VERSION ""

NS_ :

BS_:

BU_: BRAKE STEERING THROTTLE FAULT

BO_ 80 BRAKE_ENABLE: 8 BRAKE
 SG_ BRAKE_ENABLE_magic : 0|16@1+ (1,0) [0|0] "" BRAKE
 SG_ BRAKE_ENABLE_reserved : 16|48@1+ (1,0) [0|0] "" BRAKE

BO_ 81 BRAKE_DISABLE: 8 BRAKE
 SG_ BRAKE_DISABLE_magic : 0|16@1+ (1,0) [0|0] "" BRAKE
 SG_ BRAKE_DISABLE_reserved : 16|48@1+ (1,0) [0|0] "" BRAKE

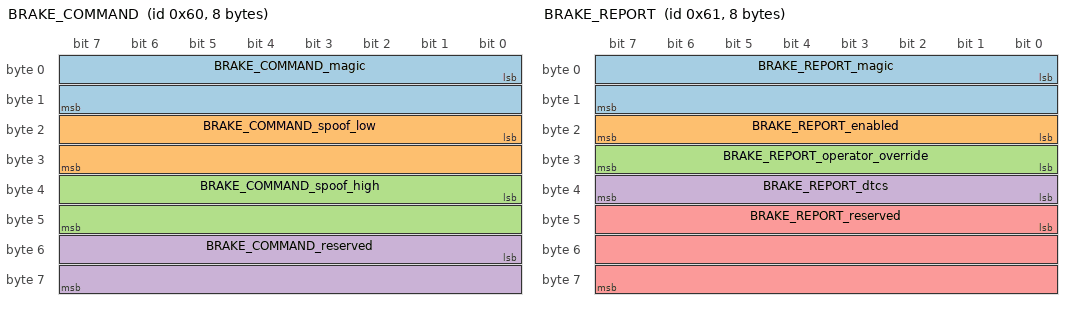
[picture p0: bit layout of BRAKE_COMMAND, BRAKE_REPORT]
BO_ 96 BRAKE_COMMAND: 8 BRAKE
 SG_ BRAKE_COMMAND_magic : 0|16@1+ (1,0) [0|0] "" BRAKE
 SG_ BRAKE_COMMAND_spoof_low : 16|16@1+ (1,0) [0|0] "" BRAKE
 SG_ BRAKE_COMMAND_spoof_high : 32|16@1+ (1,0) [0|0] "" BRAKE
 SG_ BRAKE_COMMAND_reserved : 48|16@1+ (1,0) [0|0] "" BRAKE

BO_ 97 BRAKE_REPORT: 8 BRAKE
 SG_ BRAKE_REPORT_magic : 0|16@1+ (1,0) [0|0] "" BRAKE
 SG_ BRAKE_REPORT_enabled : 16|8@1+ (1,0) [0|0] "" BRAKE
 SG_ BRAKE_REPORT_operator_override : 24|8@1+ (1,0) [0|0] "" BRAKE
 SG_ BRAKE_REPORT_dtcs : 32|8@1+ (1,0) [0|0] "" BRAKE
 SG_ BRAKE_REPORT_reserved : 40|24@1+ (1,0) [0|0] "" BRAKE

BO_ 84 STEERING_ENABLE: 8 STEERING
 SG_ STEERING_ENABLE_magic : 0|16@1+ (1,0) [0|0] "" STEERING
 SG_ STEERING_ENABLE_reserved : 16|48@1+ (1,0) [0|0] "" STEERING

BO_ 85 STEERING_DISABLE: 8 STEERING
 SG_ STEERING_DISABLE_magic : 0|16@1+ (1,0) [0|0] "" STEERING
 SG_ STEERING_DISABLE_reserved : 16|48@1+ (1,0) [0|0] "" STEERING

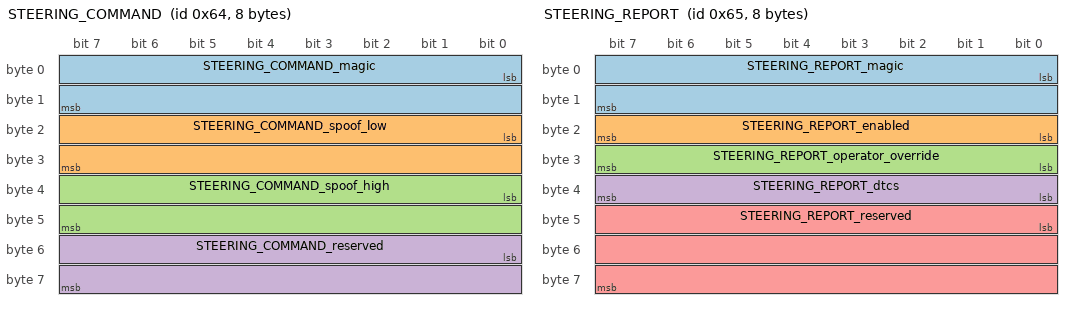
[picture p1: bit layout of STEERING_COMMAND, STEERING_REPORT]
BO_ 100 STEERING_COMMAND: 8 STEERING
 SG_ STEERING_COMMAND_magic : 0|16@1+ (1,0) [0|0] "" STEERING
 SG_ STEERING_COMMAND_spoof_low : 16|16@1+ (1,0) [0|0] "" STEERING
 SG_ STEERING_COMMAND_spoof_high : 32|16@1+ (1,0) [0|0] "" STEERING
 SG_ STEERING_COMMAND_reserved : 48|16@1+ (1,0) [0|0] "" STEERING

BO_ 101 STEERING_REPORT: 8 STEERING
 SG_ STEERING_REPORT_magic : 0|16@1+ (1,0) [0|0] "" STEERING
 SG_ STEERING_REPORT_enabled : 16|8@1+ (1,0) [0|0] "" STEERING
 SG_ STEERING_REPORT_operator_override : 24|8@1+ (1,0) [0|0] "" STEERING
 SG_ STEERING_REPORT_dtcs : 32|8@1+ (1,0) [0|0] "" STEERING
 SG_ STEERING_REPORT_reserved : 40|24@1+ (1,0) [0|0] "" STEERING

BO_ 82 THROTTLE_ENABLE: 8 THROTTLE
 SG_ THROTTLE_ENABLE_magic : 0|16@1+ (1,0) [0|0] "" THROTTLE
 SG_ THROTTLE_ENABLE_reserved : 16|48@1+ (1,0) [0|0] "" THROTTLE

BO_ 83 THROTTLE_DISABLE: 8 THROTTLE
 SG_ THROTTLE_DISABLE_magic : 0|16@1+ (1,0) [0|0] "" THROTTLE
 SG_ THROTTLE_DISABLE_reserved : 16|48@1+ (1,0) [0|0] "" THROTTLE

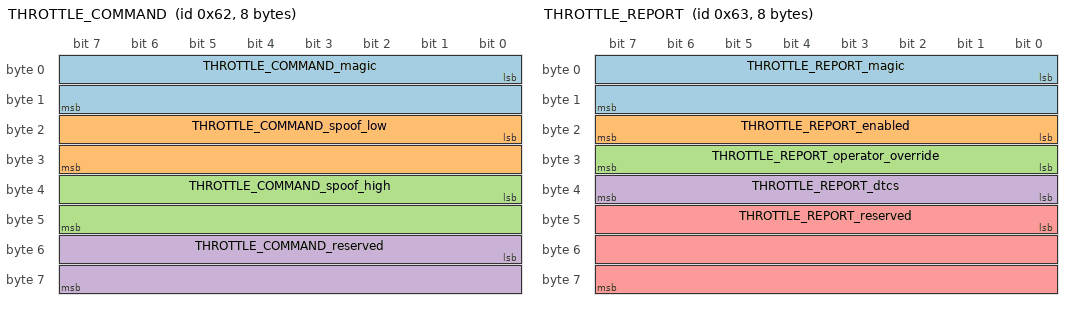
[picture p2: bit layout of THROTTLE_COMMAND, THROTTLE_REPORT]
BO_ 98 THROTTLE_COMMAND: 8 THROTTLE
 SG_ THROTTLE_COMMAND_magic : 0|16@1+ (1,0) [0|0] "" THROTTLE
 SG_ THROTTLE_COMMAND_spoof_low : 16|16@1+ (1,0) [0|0] "" THROTTLE
 SG_ THROTTLE_COMMAND_spoof_high : 32|16@1+ (1,0) [0|0] "" THROTTLE
 SG_ THROTTLE_COMMAND_reserved : 48|16@1+ (1,0) [0|0] "" THROTTLE

BO_ 99 THROTTLE_REPORT: 8 THROTTLE
 SG_ THROTTLE_REPORT_magic : 0|16@1+ (1,0) [0|0] "" THROTTLE
 SG_ THROTTLE_REPORT_enabled : 16|8@1+ (1,0) [0|0] "" THROTTLE
 SG_ THROTTLE_REPORT_operator_override : 24|8@1+ (1,0) [0|0] "" THROTTLE
 SG_ THROTTLE_REPORT_dtcs : 32|8@1+ (1,0) [0|0] "" THROTTLE
 SG_ THROTTLE_REPORT_reserved : 40|24@1+ (1,0) [0|0] "" THROTTLE

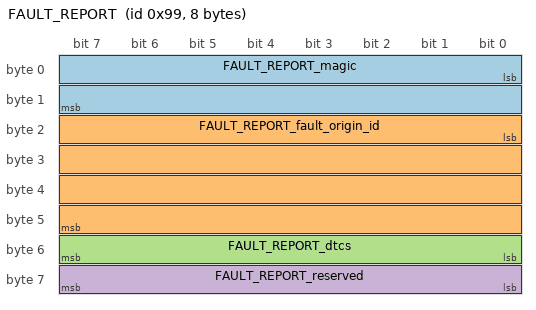
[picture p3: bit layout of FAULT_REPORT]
BO_ 153 FAULT_REPORT: 8 FAULT
 SG_ FAULT_REPORT_magic : 0|16@1+ (1,0) [0|0] "" FAULT
 SG_ FAULT_REPORT_fault_origin_id : 16|32@1+ (1,0) [0|0] "" FAULT
 SG_ FAULT_REPORT_dtcs : 48|8@1+ (1,0) [0|0] "" FAULT
 SG_ FAULT_REPORT_reserved : 56|8@1+ (1,0) [0|0] "" FAULT

CM_ BU_ BRAKE "The OSCC brake module";
CM_ BU_ STEERING "The OSCC steering module";
CM_ BU_ THROTTLE "The OSCC throttle module";
CM_ BU_ FAULT "The OSCC fault report";
